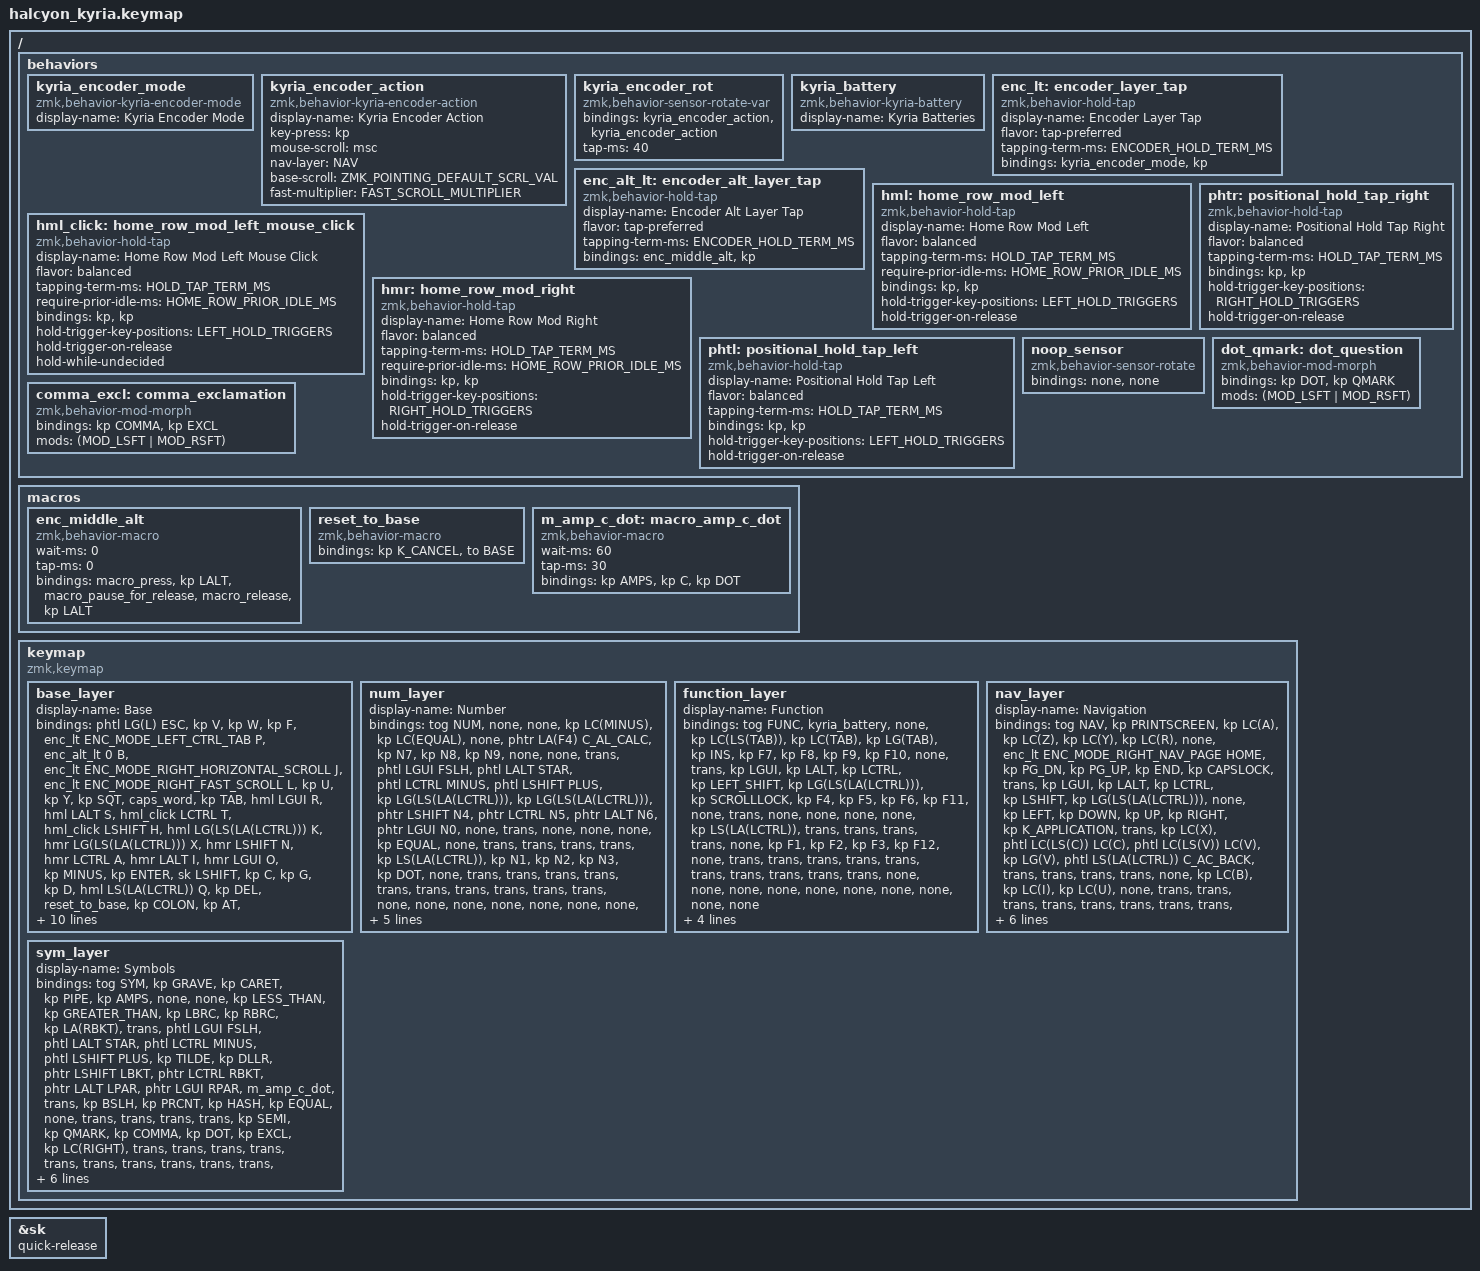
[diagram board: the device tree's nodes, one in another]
// Physical key layout, [normal] {thumb} (encoder):
// encoders:                               (50)             (59)
// row 0:    [00] [01] [02] [03] [04] [05]                       [06] [07] [08] [09] [10] [11]
// row 1:    [12] [13] [14] [15] [16] [17]                       [18] [19] [20] [21] [22] [23]
// row 2:    [24] [25] [26] [27] [28] [29] {30} {31}   {32} {33} [34] [35] [36] [37] [38] [39]
// row 3:                   {40} {41} {42} {43} {44}   {45} {46} {47} {48} {49}

#include <behaviors.dtsi>

// Custom dongle behaviour: type live battery levels of both halves.
#include <dt-bindings/zmk/keys.h>
// Scale encoder wheel pulses to produce a scroll step during a short rotation tap.
#define ZMK_POINTING_DEFAULT_SCRL_VAL 50
#include <dt-bindings/zmk/pointing.h>
// Scale the right encoder's fast scroll without changing normal scrolling.
#define FAST_SCROLL_MULTIPLIER 5
// The controller receives scroll values through its devicetree node.

#define BASE 0
#define NUM  1
#define FUNC 2
#define NAV  3
#define SYM  4
// Hold-tap mode IDs match src/kyria_encoder_state.h.
#define ENC_MODE_LEFT_CTRL_TAB           2
#define ENC_MODE_RIGHT_NAV_PAGE          4
#define ENC_MODE_RIGHT_FAST_SCROLL       5
#define ENC_MODE_RIGHT_HORIZONTAL_SCROLL 6

#define ENC_LEFT_CW   0
#define ENC_LEFT_CCW  1
#define ENC_RIGHT_CW  2
#define ENC_RIGHT_CCW 3

// Shared timing parameters (milliseconds).
// Prior-idle is used only by the home-row modifiers.
#define HOLD_TAP_TERM_MS 280 // 200
#define HOME_ROW_PRIOR_IDLE_MS 150 // 100
// Deliberate finger-held encoder modes; independent of home-row modifier timing.
#define ENCODER_HOLD_TERM_MS 250

// Opposite-hand key positions that trigger positional hold-taps.
// "Left" and "Right" refer to the hand with the hold-tap key.
#define LEFT_HRM_TRIGGERS \
     6  7  8  9 10 11 \
    18 19 20 21 22 23 \
    32 33 34 35 36 37 38 39 \
             45 46 47 48 49 \
    59 // encoder

#define RIGHT_HRM_TRIGGERS \
     0  1  2  3  4  5 \
    12 13 14 15 16 17 \
    24 25 26 27 28 29 30 31 \
             40 41 42 43 44 \
    50 // encoder

// Other positional hold-taps initially use the same opposite-hand sets.
// Keep separate names so their trigger policies can diverge later.
#define LEFT_HOLD_TRIGGERS  LEFT_HRM_TRIGGERS
#define RIGHT_HOLD_TRIGGERS RIGHT_HRM_TRIGGERS

/ {
    behaviors {
        // These behaviors are implemented on the central dongle.
        kyria_encoder_mode: kyria_encoder_mode {
            compatible = "zmk,behavior-kyria-encoder-mode";
            #binding-cells = <1>;
            display-name = "Kyria Encoder Mode";
        };

        kyria_encoder_action: kyria_encoder_action {
            compatible = "zmk,behavior-kyria-encoder-action";
            #binding-cells = <1>;
            display-name = "Kyria Encoder Action";
            key-press = <&kp>;
            mouse-scroll = <&msc>;
            nav-layer = <NAV>;
            base-scroll = <ZMK_POINTING_DEFAULT_SCRL_VAL>;
            fast-multiplier = <FAST_SCROLL_MULTIPLIER>;
        };

        // A single dispatcher receives both encoders on every keyboard layer.
        kyria_encoder_rot: kyria_encoder_rot {
            compatible = "zmk,behavior-sensor-rotate-var";
            #sensor-binding-cells = <2>;
            bindings = <&kyria_encoder_action>, <&kyria_encoder_action>;
            tap-ms = <40>;
        };

        kyria_battery: kyria_battery {
            compatible = "zmk,behavior-kyria-battery";
            #binding-cells = <0>;
            display-name = "Kyria Batteries";
        };

        // Tap normally, or hold to change the adjacent encoder's action.
        // Tap-preferred avoids activating encoder modes during rapid typing.
        enc_lt: encoder_layer_tap {
            compatible = "zmk,behavior-hold-tap";
            #binding-cells = <2>;
            display-name = "Encoder Layer Tap";
            flavor = "tap-preferred";
            tapping-term-ms = <ENCODER_HOLD_TERM_MS>;
            bindings = <&kyria_encoder_mode>, <&kp>;
        };

        // B holds Alt; the encoder controller independently tracks physical B.
        // The hold behavior has no parameters; the keymap passes dummy 0.
        enc_alt_lt: encoder_alt_layer_tap {
            compatible = "zmk,behavior-hold-tap";
            #binding-cells = <2>;
            display-name = "Encoder Alt Layer Tap";
            flavor = "tap-preferred";
            tapping-term-ms = <ENCODER_HOLD_TERM_MS>;
            bindings = <&enc_middle_alt>, <&kp>;
        };

        // Home-row mods.
        hml: home_row_mod_left {
            compatible = "zmk,behavior-hold-tap";
            #binding-cells = <2>;
            display-name = "Home Row Mod Left";

            flavor = "balanced";
            tapping-term-ms = <HOLD_TAP_TERM_MS>;
            require-prior-idle-ms = <HOME_ROW_PRIOR_IDLE_MS>;

            bindings = <&kp>, <&kp>;

            hold-trigger-key-positions = <LEFT_HOLD_TRIGGERS>;

            hold-trigger-on-release;
        };

        // Immediate modifiers for Ctrl-click and Shift-click.
        // Keep this separate from other left home-row modifiers to avoid
        // changing their tap/hold behaviour during normal typing.
        hml_click: home_row_mod_left_mouse_click {
            compatible = "zmk,behavior-hold-tap";
            #binding-cells = <2>;
            display-name = "Home Row Mod Left Mouse Click";

            flavor = "balanced";
            tapping-term-ms = <HOLD_TAP_TERM_MS>;
            require-prior-idle-ms = <HOME_ROW_PRIOR_IDLE_MS>;

            bindings = <&kp>, <&kp>;
            hold-trigger-key-positions = <LEFT_HOLD_TRIGGERS>;
            hold-trigger-on-release;
            hold-while-undecided;
        };

        hmr: home_row_mod_right {
            compatible = "zmk,behavior-hold-tap";
            #binding-cells = <2>;
            display-name = "Home Row Mod Right";

            flavor = "balanced";
            tapping-term-ms = <HOLD_TAP_TERM_MS>;
            require-prior-idle-ms = <HOME_ROW_PRIOR_IDLE_MS>;

            bindings = <&kp>, <&kp>;

            hold-trigger-key-positions = <RIGHT_HOLD_TRIGGERS>;

            hold-trigger-on-release;
        };

        // Hold-taps
        phtl: positional_hold_tap_left {
            compatible = "zmk,behavior-hold-tap";
            #binding-cells = <2>;
            display-name = "Positional Hold Tap Left";

            flavor = "balanced";
            tapping-term-ms = <HOLD_TAP_TERM_MS>;

            bindings = <&kp>, <&kp>;

            hold-trigger-key-positions = <LEFT_HOLD_TRIGGERS>;

            hold-trigger-on-release;
        };

        phtr: positional_hold_tap_right {
            compatible = "zmk,behavior-hold-tap";
            #binding-cells = <2>;
            display-name = "Positional Hold Tap Right";

            flavor = "balanced";
            tapping-term-ms = <HOLD_TAP_TERM_MS>;

            bindings = <&kp>, <&kp>;

            hold-trigger-key-positions = <RIGHT_HOLD_TRIGGERS>;

            hold-trigger-on-release;
        };

        /*
         * Ignore rotation for unused encoders / intentionally disabled layers
         */
        noop_sensor: noop_sensor {
            compatible = "zmk,behavior-sensor-rotate";
            #sensor-binding-cells = <0>;
            bindings = <&none>, <&none>;
        };

        // Shift-dependent punctuation on the Base layer.
        dot_qmark: dot_question {
            compatible = "zmk,behavior-mod-morph";
            #binding-cells = <0>;
            bindings = <&kp DOT>, <&kp QMARK>;
            mods = <(MOD_LSFT | MOD_RSFT)>;
        };

        comma_excl: comma_exclamation {
            compatible = "zmk,behavior-mod-morph";
            #binding-cells = <0>;
            bindings = <&kp COMMA>, <&kp EXCL>;
            mods = <(MOD_LSFT | MOD_RSFT)>;
        };
    };

    /*
     * This is the one Voyager macro retained:
     * "&c."
     */
    macros {
        // Select a window by releasing Alt when the held B key is released.
        // The encoder controller tracks the physical B hold separately.
        enc_middle_alt: enc_middle_alt {
            compatible = "zmk,behavior-macro";
            #binding-cells = <0>;
            wait-ms = <0>;
            tap-ms = <0>;
            bindings =
                <&macro_press &kp LALT>,
                <&macro_pause_for_release>,
                <&macro_release &kp LALT>;
        };

        reset_to_base: reset_to_base {
            compatible = "zmk,behavior-macro";
            #binding-cells = <0>;
            bindings = <&kp K_CANCEL &to BASE>;
        };

        m_amp_c_dot: macro_amp_c_dot {
            compatible = "zmk,behavior-macro";
            #binding-cells = <0>;
            wait-ms = <60>;
            tap-ms = <30>;
            bindings = <&kp AMPS &kp C &kp DOT>;
        };
    };

    keymap {
        compatible = "zmk,keymap";

        /*
         * Each layer's bindings property is one flat 60-position list.
         * Formatting is purely for humans: one position per line, comments
         * show absolute position numbers, and a blank line separates hands.
         */

        base_layer {
            display-name = "Base";

            bindings = <
                // Row 0, left - positions 0-5
                &phtl LG(L) ESC   // 0
                &kp V             // 1
                &kp W             // 2
                &kp F             // 3
                &enc_lt ENC_MODE_LEFT_CTRL_TAB P // 4
                &enc_alt_lt 0 B     // 5

                // Row 0, right - positions 6-11
                &enc_lt ENC_MODE_RIGHT_HORIZONTAL_SCROLL J // 6
                &enc_lt ENC_MODE_RIGHT_FAST_SCROLL L // 7
                &kp U             // 8
                &kp Y             // 9
                &kp SQT           // 10
                &caps_word        // 11

                // Row 1, left - positions 12-17
                &kp TAB           // 12
                &hml LGUI R       // 13
                &hml LALT S       // 14
                &hml_click LCTRL T      // 15
                &hml_click LSHIFT H     // 16
                &hml LG(LS(LA(LCTRL))) K      // 17

                // Row 1, right - positions 18-23
                &hmr LG(LS(LA(LCTRL))) X      // 18
                &hmr LSHIFT N     // 19
                &hmr LCTRL A      // 20
                &hmr LALT I       // 21
                &hmr LGUI O       // 22
                &kp MINUS         // 23

                // Row 2, left - positions 24-29
                &kp ENTER         // 24
                &sk LSHIFT        // 25
                &kp C             // 26
                &kp G             // 27
                &kp D             // 28
                &hml LS(LA(LCTRL)) Q        // 29

                // Upper thumbs, left - positions 30-31
                &kp DEL           // 30
                &reset_to_base    // 31
                // Upper thumbs, right - positions 32-33
                &kp COLON         // 32
                &kp AT            // 33
                // Row 2, right - positions 34-39
                &hmr LS(LA(LCTRL)) Z        // 34
                &kp M             // 35
                &comma_excl       // 36
                &dot_qmark        // 37
                &sk LSHIFT        // 38
                &kp LGUI          // 39
                // Thumbs, left - positions 40-44
                &none             // 40
                &sl FUNC          // 41
                &sl NUM           // 42
                &kp E             // 43
                &sl NAV           // 44

                // Thumbs, right - positions 45-49
                &sl SYM           // 45
                &kp SPACE         // 46
                &kp BACKSPACE     // 47
                &none             // 48
                &none             // 49
                // Encoder, left push action - position 50
                &kp LG(TAB)       // 50
                // Blank, left - unused encoder key positions 51-54
                &none             // 51
                &none             // 52
                &none             // 53
                &none             // 54

                // Blank, right - unused encoder key positions 55-58
                &none             // 55
                &none             // 56
                &none             // 57
                &none             // 58

                // Encoder, right push action - position 59
                &none             // 59
            >;

            sensor-bindings =
                // Left Halcyon encoder: dynamic dispatch
                <&kyria_encoder_rot ENC_LEFT_CW ENC_LEFT_CCW>,
                // Right Halcyon encoder: dynamic dispatch
                <&kyria_encoder_rot ENC_RIGHT_CW ENC_RIGHT_CCW>,
                // Unused left soldered encoder
                <&noop_sensor>,
                // Unused right soldered encoder
                <&noop_sensor>;
        };

        /*
         * NUMBERS AND ARITHMETIC
         * Old Voyager layer 3.
         */
        num_layer {
            display-name = "Number";

            bindings = <
                // Row 0, left - positions 0-5
                &tog NUM                    // 0
                &none                       // 1
                &none             // 02
                &kp LC(MINUS)               // 3
                &kp LC(EQUAL)               // 4
                &none                       // 5

                // Row 0, right - positions 6-11
                &phtr LA(F4) C_AL_CALC      // 6
                &kp N7                      // 7
                &kp N8                      // 8
                &kp N9                      // 9
                &none                         // 10
                &none                       // 11

                // Row 1, left - positions 12-17
                &trans            // 12
                &phtl LGUI FSLH             // 13
                &phtl LALT STAR             // 14
                &phtl LCTRL MINUS           // 15
                &phtl LSHIFT PLUS           // 16
                &kp LG(LS(LA(LCTRL)))         // 17

                // Row 1, right - positions 18-23
                &kp LG(LS(LA(LCTRL)))                   // 18
                &phtr LSHIFT N4             // 19
                &phtr LCTRL N5              // 20
                &phtr LALT N6               // 21
                &phtr LGUI N0               // 22
                &none                       // 23

                // Row 2, left - positions 24-29
                &trans                      // 24
                &none                         // 25
                &none                         // 26
                &none                         // 27
                &kp EQUAL                     // 28
                &none                         // 29

                // Upper thumbs, left - positions 30-31
                &trans            // 30
                &trans            // 31
                // Upper thumbs, right - positions 32-33
                &trans            // 32
                &trans            // 33
                // Row 2, right - positions 34-39
                &kp LS(LA(LCTRL))                     // 34
                &kp N1                      // 35
                &kp N2                      // 36
                &kp N3                      // 37
                &kp DOT                     // 38
                &none                       // 39

                // Thumbs, left - positions 40-44
                &trans            // 40
                &trans                      // 41
                &trans                      // 42
                &trans                      // 43
                &trans                      // 44

                // Thumbs, right - positions 45-49
                &trans                      // 45
                &trans                      // 46
                &trans            // 47
                &trans                      // 48
                &trans            // 49
                // Encoder, left push action - position 50
                &none             // 50
                // Blank, left - unused encoder key positions 51-54
                &none                       // 51
                &none                       // 52
                &none                       // 53
                &none                       // 54

                // Blank, right - unused encoder key positions 55-58
                &none                       // 55
                &none                       // 56
                &none                       // 57
                &none                       // 58

                // Encoder, right push action - position 59
                &none             // 59
            >;

            sensor-bindings =
                // Left Halcyon encoder: dynamic dispatch
                <&kyria_encoder_rot ENC_LEFT_CW ENC_LEFT_CCW>,
                // Right Halcyon encoder: dynamic dispatch
                <&kyria_encoder_rot ENC_RIGHT_CW ENC_RIGHT_CCW>,
                // Unused left soldered encoder
                <&noop_sensor>,
                // Unused right soldered encoder
                <&noop_sensor>;

        };

        /*
         * FUNCTION
         * Old Voyager layer 4.
         *
         * The two old RGB controls are now &none.
         */
        function_layer {
            display-name = "Function";

            bindings = <
                // Row 0, left - positions 0-5
                &tog FUNC                   // 0
                &kyria_battery    // 01
                &none                       // 2
                &kp LC(LS(TAB))             // 3
                &kp LC(TAB)                 // 4
                &kp LG(TAB)                 // 5

                // Row 0, right - positions 6-11
                &kp INS                     // 6
                &kp F7                      // 7
                &kp F8                      // 8
                &kp F9                      // 9
                &kp F10                     // 10
                &none             // 11
                // Row 1, left - positions 12-17
                &trans            // 12
                &kp LGUI                    // 13
                &kp LALT                    // 14
                &kp LCTRL               // 15
                &kp LEFT_SHIFT            // 16
                &kp LG(LS(LA(LCTRL)))                   // 17

                // Row 1, right - positions 18-23
                &kp SCROLLLOCK              // 18
                &kp F4                      // 19
                &kp F5                      // 20
                &kp F6                      // 21
                &kp F11                     // 22
                &none                       // 23

                // Row 2, left - positions 24-29
                &trans                      // 24
                &none                       // 25
                &none                       // 26
                &none              // 27
                &none             // 28
                &kp LS(LA(LCTRL))                     // 29

                // Upper thumbs, left - positions 30-31
                &trans            // 30
                &trans            // 31
                // Upper thumbs, right - positions 32-33
                &trans            // 32
                &trans            // 33
                // Row 2, right - positions 34-39
                &none                       // 34
                &kp F1                      // 35
                &kp F2                      // 36
                &kp F3                      // 37
                &kp F12                     // 38
                &none                       // 39

                // Thumbs, left - positions 40-44
                &trans            // 40
                &trans                      // 41
                &trans                      // 42
                &trans                      // 43
                &trans                      // 44

                // Thumbs, right - positions 45-49
                &trans                      // 45
                &trans                      // 46
                &trans            // 47
                &trans                      // 48
                &trans            // 49
                // Encoder, left push action - position 50
                &none             // 50
                // Blank, left - unused encoder key positions 51-54
                &none                       // 51
                &none                       // 52
                &none                       // 53
                &none                       // 54

                // Blank, right - unused encoder key positions 55-58
                &none                       // 55
                &none                       // 56
                &none                       // 57
                &none                       // 58

                // Encoder, right push action - position 59
                &none             // 59
            >;

            sensor-bindings =
                // Left Halcyon encoder: dynamic dispatch
                <&kyria_encoder_rot ENC_LEFT_CW ENC_LEFT_CCW>,
                // Right Halcyon encoder: dynamic dispatch
                <&kyria_encoder_rot ENC_RIGHT_CW ENC_RIGHT_CCW>,
                // Unused left soldered encoder
                <&noop_sensor>,
                // Unused right soldered encoder
                <&noop_sensor>;

        };

        /*
         * NAVIGATION
         * Old Voyager layer 5.
         */
        nav_layer {
            display-name = "Navigation";

            bindings = <
                // Row 0, left - positions 0-5
                &tog NAV               // 0
                &kp PRINTSCREEN        // 1
                &kp LC(A)              // 2
                &kp LC(Z)              // 3
                &kp LC(Y)              // 4
                &kp LC(R)              // 5

                // Row 0, right - positions 6-11
                // Position 06: physical hold selects NAV vertical arrows.
                &none             // 06
                &enc_lt ENC_MODE_RIGHT_NAV_PAGE HOME // 7
                &kp PG_DN              // 8
                &kp PG_UP              // 9
                &kp END                // 10
                &kp CAPSLOCK           // 11

                // Row 1, left - positions 12-17
                &trans            // 12
                &kp LGUI               // 13
                &kp LALT               // 14
                &kp LCTRL              // 15
                &kp LSHIFT             // 16
                &kp LG(LS(LA(LCTRL)))              // 17

                // Row 1, right - positions 18-23
                &none             // 18
                &kp LEFT               // 19
                &kp DOWN               // 20
                &kp UP                 // 21
                &kp RIGHT              // 22
                &kp K_APPLICATION      // 23

                // Row 2, left - positions 24-29
                &trans                 // 24
                &kp LC(X)              // 25
                &phtl LC(LS(C)) LC(C)  // 26
                &phtl LC(LS(V)) LC(V)  // 27
                &kp LG(V)              // 28
                &phtl LS(LA(LCTRL)) C_AC_BACK    // 29

                // Upper thumbs, left - positions 30-31
                &trans            // 30
                &trans            // 31
                // Upper thumbs, right - positions 32-33
                &trans            // 32
                &trans            // 33
                // Row 2, right - positions 34-39
                &none             // 34
                &kp LC(B)         // 35
                &kp LC(I)         // 36
                &kp LC(U)         // 37
                &none                  // 38
                &trans                 // 39

                // Thumbs, left - positions 40-44
                &trans            // 40
                &trans                 // 41
                &trans                 // 42
                &trans                 // 43
                &trans                 // 44

                // Thumbs, right - positions 45-49
                &trans                 // 45
                &trans                 // 46
                &trans            // 47
                &trans            // 48
                &trans            // 49
                // Encoder, left push action - position 50
                &none             // 50
                // Blank, left - unused encoder key positions 51-54
                &none                  // 51
                &none                  // 52
                &none                  // 53
                &none                  // 54

                // Blank, right - unused encoder key positions 55-58
                &none                  // 55
                &none                  // 56
                &none                  // 57
                &none                  // 58

                // Encoder, right push action - position 59
                &none             // 59
            >;

            sensor-bindings =
                // Left Halcyon encoder: dynamic dispatch
                <&kyria_encoder_rot ENC_LEFT_CW ENC_LEFT_CCW>,
                // Right Halcyon encoder: dynamic dispatch
                <&kyria_encoder_rot ENC_RIGHT_CW ENC_RIGHT_CCW>,
                // Unused left soldered encoder
                <&noop_sensor>,
                // Unused right soldered encoder
                <&noop_sensor>;

        };

        /*
         * SYMBOLS
         * Left: operators. Right: brackets, punctuation and shortcuts.
         */
        sym_layer {
            display-name = "Symbols";

            bindings = <
                // Row 0, left - positions 0-5
                &tog SYM           // 0
                &kp GRAVE                     // 1
                &kp CARET                     // 2
                &kp PIPE                      // 3
                &kp AMPS                      // 4
                &none              // 5

                // Row 0, right - positions 6-11
                &none              // 6
                &kp LESS_THAN                 // 7
                &kp GREATER_THAN              // 8
                &kp LBRC           // 9
                &kp RBRC           // 10
                &kp LA(RBKT)       // 11

                // Row 1, left - positions 12-17
                &trans            // 12
                &phtl LGUI FSLH               // 13
                &phtl LALT STAR               // 14
                &phtl LCTRL MINUS             // 15
                &phtl LSHIFT PLUS             // 16
                &kp TILDE                     // 17

                // Row 1, right - positions 18-23
                &kp DLLR                      // 18
                &phtr LSHIFT LBKT             // 19
                &phtr LCTRL RBKT              // 20
                &phtr LALT LPAR    // 21
                &phtr LGUI RPAR    // 22
                &m_amp_c_dot       // 23

                // Row 2, left - positions 24-29
                &trans             // 24
                &kp BSLH                      // 25
                &kp PRCNT                     // 26
                &kp HASH                      // 27
                &kp EQUAL                     // 28
                &none                         // 29

                // Upper thumbs, left - positions 30-31
                &trans             // 30
                &trans             // 31

                // Upper thumbs, right - positions 32-33
                &trans             // 32
                &trans             // 33

                // Row 2, right - positions 34-39
                &kp SEMI                      // 34
                &kp QMARK                     // 35
                &kp COMMA                     // 36
                &kp DOT                       // 37
                &kp EXCL                      // 38
                &kp LC(RIGHT)      // 39

                // Thumbs, left - positions 40-44
                &trans              // 40
                &trans             // 41
                &trans             // 42
                &trans             // 43
                &trans             // 44

                // Thumbs, right - positions 45-49
                &trans             // 45
                &trans             // 46
                &trans              // 47
                &trans             // 48
                &trans              // 49

                // Encoder, left push action - position 50
                &none             // 50
                // Blank, left - unused encoder key positions 51-54
                &none              // 51
                &none              // 52
                &none              // 53
                &none              // 54

                // Blank, right - unused encoder key positions 55-58
                &none              // 55
                &none              // 56
                &none              // 57
                &none              // 58

                // Encoder, right push action - position 59
                &none             // 59
            >;

            sensor-bindings =
                // Left Halcyon encoder: dynamic dispatch
                <&kyria_encoder_rot ENC_LEFT_CW ENC_LEFT_CCW>,
                // Right Halcyon encoder: dynamic dispatch
                <&kyria_encoder_rot ENC_RIGHT_CW ENC_RIGHT_CCW>,
                // Unused left soldered encoder
                <&noop_sensor>,
                // Unused right soldered encoder
                <&noop_sensor>;

        };

    };
};

// Release sticky modifiers immediately after the next key press, rather
// than waiting for that key to be released. Applies to both &sk LSHIFT keys.
&sk {
    quick-release;
};
